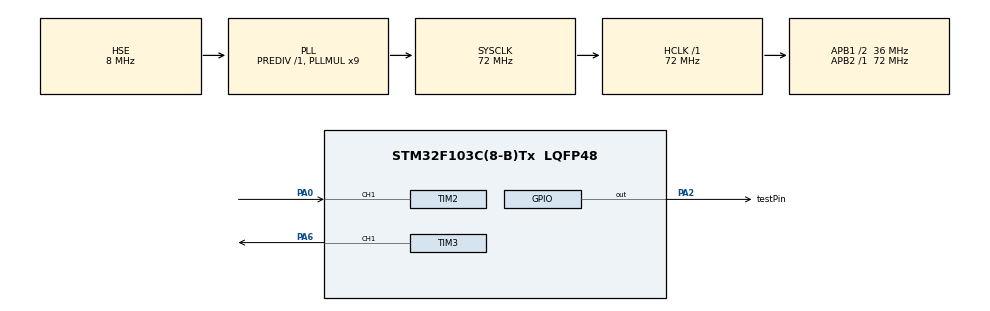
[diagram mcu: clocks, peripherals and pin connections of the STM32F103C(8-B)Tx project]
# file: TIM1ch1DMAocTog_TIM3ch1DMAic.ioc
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Dma.Request0=TIM2_CH1
Dma.Request1=TIM2_CH2/CH4
Dma.Request2=TIM3_CH1/TRIG
Dma.TIM2_CH1.0.Direction=DMA_PERIPH_TO_MEMORY
Dma.TIM2_CH1.0.Instance=DMA1_Channel5
Dma.TIM2_CH1.0.MemDataAlignment=DMA_MDATAALIGN_WORD
Dma.TIM2_CH1.0.MemInc=DMA_MINC_ENABLE
Dma.TIM2_CH1.0.Mode=DMA_CIRCULAR
Dma.TIM2_CH1.0.PeriphDataAlignment=DMA_PDATAALIGN_HALFWORD
Dma.TIM2_CH1.0.PeriphInc=DMA_PINC_DISABLE
Dma.TIM2_CH1.0.Priority=DMA_PRIORITY_HIGH
Dma.TIM2_CH2/CH4.1.Direction=DMA_PERIPH_TO_MEMORY
Dma.TIM2_CH2/CH4.1.Instance=DMA1_Channel7
Dma.TIM2_CH2/CH4.1.MemDataAlignment=DMA_MDATAALIGN_WORD
Dma.TIM2_CH2/CH4.1.MemInc=DMA_MINC_ENABLE
Dma.TIM2_CH2/CH4.1.Mode=DMA_CIRCULAR
Dma.TIM2_CH2/CH4.1.PeriphDataAlignment=DMA_PDATAALIGN_HALFWORD
Dma.TIM2_CH2/CH4.1.PeriphInc=DMA_PINC_DISABLE
Dma.TIM2_CH2/CH4.1.Priority=DMA_PRIORITY_HIGH
Dma.TIM3_CH1/TRIG.2.Direction=DMA_MEMORY_TO_PERIPH
Dma.TIM3_CH1/TRIG.2.Instance=DMA1_Channel6
Dma.TIM3_CH1/TRIG.2.MemDataAlignment=DMA_MDATAALIGN_WORD
Dma.TIM3_CH1/TRIG.2.MemInc=DMA_MINC_ENABLE
Dma.TIM3_CH1/TRIG.2.Mode=DMA_CIRCULAR
Dma.TIM3_CH1/TRIG.2.PeriphDataAlignment=DMA_PDATAALIGN_HALFWORD
Dma.TIM3_CH1/TRIG.2.PeriphInc=DMA_PINC_DISABLE
Dma.TIM3_CH1/TRIG.2.Priority=DMA_PRIORITY_HIGH
Mcu.Family=STM32F1
Mcu.Name=STM32F103C(8-B)Tx
Mcu.Package=LQFP48
NVIC.DMA1_Channel5_IRQn=true\:0\:0\:false\:false\:true
NVIC.DMA1_Channel6_IRQn=true\:0\:0\:false\:false\:true
NVIC.DMA1_Channel7_IRQn=true\:0\:0\:false\:false\:true
NVIC.PriorityGroup=NVIC_PRIORITYGROUP_4
PA0-WKUP.Signal=S_TIM2_CH1_ETR
PA13.Mode=Serial_Wire
PA13.Signal=SYS_JTMS-SWDIO
PA14.Mode=Serial_Wire
PA14.Signal=SYS_JTCK-SWCLK
PA2.GPIO_Label=testPin
PA2.GPIO_Speed=GPIO_SPEED_FREQ_HIGH
PA2.PinState=GPIO_PIN_SET
PA2.Signal=GPIO_Output
PA6.GPIO_Speed=GPIO_SPEED_FREQ_HIGH
PA6.Signal=S_TIM3_CH1
PD0-OSC_IN.Mode=HSE-External-Oscillator
PD0-OSC_IN.Signal=RCC_OSC_IN
PD1-OSC_OUT.Mode=HSE-External-Oscillator
PD1-OSC_OUT.Signal=RCC_OSC_OUT
ProjectManager.HeapSize=0x200
ProjectManager.StackSize=0x400
ProjectManager.TargetToolchain=SW4STM32
RCC.AHBFreq_Value=72000000
RCC.APB1CLKDivider=RCC_HCLK_DIV2
RCC.APB1Freq_Value=36000000
RCC.APB1TimFreq_Value=72000000
RCC.APB2Freq_Value=72000000
RCC.APB2TimFreq_Value=72000000
RCC.HCLKFreq_Value=72000000
RCC.PLLMUL=RCC_PLL_MUL9
RCC.PLLSourceVirtual=RCC_PLLSOURCE_HSE
RCC.SYSCLKFreq_VALUE=72000000
RCC.SYSCLKSource=RCC_SYSCLKSOURCE_PLLCLK
RCC.USBFreq_Value=72000000
SH.S_TIM2_CH1_ETR.0=TIM2_CH1,Input_Capture1_from_TI1
SH.S_TIM2_CH1_ETR.1=TIM2_CH1,Input_Capture2_from_TI1
SH.S_TIM2_CH1_ETR.2=TIM2_CH1,TriggerSource_TI1FP1
SH.S_TIM3_CH1.0=TIM3_CH1,Output Compare1 CH1
TIM2.Channel-Input_Capture1_from_TI1=TIM_CHANNEL_1
TIM2.Channel-Input_Capture2_from_TI1=TIM_CHANNEL_2
TIM2.ICPolarity_CH1=TIM_INPUTCHANNELPOLARITY_FALLING
TIM2.TIM_MasterOutputTrigger=TIM_TRGO_RESET
TIM3.Channel-Output\ Compare1\ CH1=TIM_CHANNEL_1
TIM3.OCMode_1=TIM_OCMODE_TOGGLE
TIM3.TIM_MasterOutputTrigger=TIM_TRGO_OC1
VP_TIM2_VS_ControllerModeReset.Mode=Reset Mode
board=TIM1ch1DMAocTog_TIM3ch1DMAic

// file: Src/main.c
/**
  ******************************************************************************
  * File Name          : main.c
  * Description        : Main program body
  ******************************************************************************
  ** This notice applies to any and all portions of this file
  * that are not between comment pairs USER CODE BEGIN and
  * USER CODE END. Other portions of this file, whether
  * inserted by the user or by software development tools
  * are owned by their respective copyright owners.
  *
  * COPYRIGHT(c) 2017 STMicroelectronics
  *
  * Redistribution and use in source and binary forms, with or without modification,
  * are permitted provided that the following conditions are met:
  *   1. Redistributions of source code must retain the above copyright notice,
  *      this list of conditions and the following disclaimer.
  *   2. Redistributions in binary form must reproduce the above copyright notice,
  *      this list of conditions and the following disclaimer in the documentation
  *      and/or other materials provided with the distribution.
  *   3. Neither the name of STMicroelectronics nor the names of its contributors
  *      may be used to endorse or promote products derived from this software
  *      without specific prior written permission.
  *
  * THIS SOFTWARE IS PROVIDED BY THE COPYRIGHT HOLDERS AND CONTRIBUTORS "AS IS"
  * AND ANY EXPRESS OR IMPLIED WARRANTIES, INCLUDING, BUT NOT LIMITED TO, THE
  * IMPLIED WARRANTIES OF MERCHANTABILITY AND FITNESS FOR A PARTICULAR PURPOSE ARE
  * DISCLAIMED. IN NO EVENT SHALL THE COPYRIGHT HOLDER OR CONTRIBUTORS BE LIABLE
  * FOR ANY DIRECT, INDIRECT, INCIDENTAL, SPECIAL, EXEMPLARY, OR CONSEQUENTIAL
  * DAMAGES (INCLUDING, BUT NOT LIMITED TO, PROCUREMENT OF SUBSTITUTE GOODS OR
  * SERVICES; LOSS OF USE, DATA, OR PROFITS; OR BUSINESS INTERRUPTION) HOWEVER
  * CAUSED AND ON ANY THEORY OF LIABILITY, WHETHER IN CONTRACT, STRICT LIABILITY,
  * OR TORT (INCLUDING NEGLIGENCE OR OTHERWISE) ARISING IN ANY WAY OUT OF THE USE
  * OF THIS SOFTWARE, EVEN IF ADVISED OF THE POSSIBILITY OF SUCH DAMAGE.
  *
  ******************************************************************************
  */
#include "main.h"
#include "stm32f1xx_hal.h"

TIM_HandleTypeDef htim2;
TIM_HandleTypeDef htim3;
DMA_HandleTypeDef hdma_tim2_ch1;
DMA_HandleTypeDef hdma_tim2_ch2_ch4;
DMA_HandleTypeDef hdma_tim3_ch1_trig;

/* USER CODE BEGIN PV */
/* Private variables ---------------------------------------------------------*/
/* Timer handler declaration */
TIM_HandleTypeDef TimHandle3;
TIM_HandleTypeDef TimHandle2;

/* Timer Output Compare Configuration Structure declaration */
TIM_OC_InitTypeDef sConfig;
TIM_IC_InitTypeDef sICConfig;

/* Capture Compare buffer */
uint32_t aCCValue_Buffer[2] = { 0, 0};//, 0 };
uint32_t icBuffer1[4] = {0, 0, 0, 0};
uint32_t icBuffer2[4] = {0, 0, 0, 0};

/* Timer Period*/
uint32_t uhTimerPeriod = 0;

uint32_t counter = 0;
uint32_t uhCapture = 0;

/* USER CODE END PV */

void SystemClock_Config(void);
static void MX_GPIO_Init(void);
static void MX_DMA_Init(void);
static void MX_TIM2_Init(void);
static void MX_TIM3_Init(void);

void HAL_TIM_MspPostInit(TIM_HandleTypeDef *htim);

/* USER CODE BEGIN PFP */
/* Private function prototypes -----------------------------------------------*/

/* USER CODE END PFP */

/* USER CODE BEGIN 0 */
int c = 0;
/* USER CODE END 0 */

int main(void)
{

  /* MCU Configuration----------------------------------------------------------*/

  /* Reset of all peripherals, Initializes the Flash interface and the Systick. */
  HAL_Init();

  /* Configure the system clock */
  SystemClock_Config();

  /* Initialize all configured peripherals */
  MX_GPIO_Init();
  MX_DMA_Init();
  MX_TIM2_Init();
  MX_TIM3_Init();

  /* USER CODE BEGIN 2 */
  	uhTimerPeriod = (uint32_t) ((SystemCoreClock / 360000) - 1);
  	//minumum pulse to put is 12??
  	aCCValue_Buffer[0] =  //12;//2;//8999;
  			(uint32_t) (((uint32_t) 10 * (uhTimerPeriod - 1)) / 100);
  	aCCValue_Buffer[1] = //(uint32_t) ((SystemCoreClock / 4000000) - 1 + aCCValue_Buffer[0]);
  			(uint32_t) (((uint32_t) 30 * (uhTimerPeriod - 1)) / 100);
//  	aCCValue_Buffer[2] = //(uint32_t) ((SystemCoreClock / 400000) - 1 + aCCValue_Buffer[1]);
//  			(uint32_t) (((uint32_t) 75 * (uhTimerPeriod - 1)) / 100);
//  	aCCValue_Buffer[3] = //17998;
//  				(uint32_t) (((uint32_t) 95 * (uhTimerPeriod - 1)) / 100);

  	TimHandle3.Instance = TIM3;
//  	TIM3->CNT = 0;
  	TimHandle3.Init.Period = uhTimerPeriod;
  	TimHandle3.Init.RepetitionCounter = 0;
  	TimHandle3.Init.Prescaler = 0;
  	TimHandle3.Init.ClockDivision = 0;
  	TimHandle3.Init.CounterMode = TIM_COUNTERMODE_UP;
  	if (HAL_TIM_OC_Init(&TimHandle3) != HAL_OK) {
  		/* Initialization Error */
  		Error_Handler();
  	}

	__HAL_TIM_CLEAR_FLAG(&TimHandle3, TIM_FLAG_UPDATE);
  	sConfig.OCMode = TIM_OCMODE_FORCED_ACTIVE;
  	sConfig.OCPolarity = TIM_OCPOLARITY_HIGH;//TIM_OCPOLARITY_HIGH;
//  	sConfig.Pulse = uhTimerPeriod;

	if (HAL_TIM_OC_ConfigChannel(&TimHandle3, &sConfig, TIM_CHANNEL_1) != HAL_OK)
  	{
  		Error_Handler();
  	}
  	if (HAL_TIM_OC_Start(&TimHandle3, TIM_CHANNEL_1))//, TIM_CHANNEL_1, aCCValue_Buffer, 4) != HAL_OK)
  	{
  		Error_Handler();
  	}

//  	while(__HAL_TIM_GET_FLAG(&TimHandle3, TIM_FLAG_CC1) != SET);
  	HAL_GPIO_WritePin(testPin_Port, testPin, GPIO_PIN_SET);

  	sConfig.OCMode = TIM_OCMODE_FORCED_INACTIVE;
//  	sConfig.OCPolarity = TIM_OCPOLARITY_HIGH;//TIM_OCPOLARITY_HIGH;
//  	sConfig.Pulse = uhTimerPeriod;

	if (HAL_TIM_OC_ConfigChannel(&TimHandle3, &sConfig, TIM_CHANNEL_1) != HAL_OK)
  	{
  		Error_Handler();
  	}
  	if (HAL_TIM_OC_Start(&TimHandle3, TIM_CHANNEL_1))//, TIM_CHANNEL_1, aCCValue_Buffer, 4) != HAL_OK)
  	{
  		Error_Handler();
  	}

//  	while(__HAL_TIM_GET_FLAG(&TimHandle3, TIM_FLAG_CC1) != SET);
  	HAL_GPIO_WritePin(testPin_Port, testPin, GPIO_PIN_RESET);

//  	sConfig.OCMode = TIM_OCMODE_TOGGLE;
//  	sConfig.OCPolarity = TIM_OCPOLARITY_HIGH;
//  	sConfig.Pulse = aCCValue_Buffer[0];//0;//aCCValue_Buffer[0];
//  	if (HAL_TIM_OC_ConfigChannel(&TimHandle3, &sConfig, TIM_CHANNEL_1) != HAL_OK)
//  	{
//  		/* Configuration Error */
//  		Error_Handler();
//  	}
//
//  	/*##-3- Start PWM signal generation in DMA mode ############################*/
//  	if (HAL_TIM_OC_Start_DMA(&TimHandle3, TIM_CHANNEL_1, aCCValue_Buffer, 3) != HAL_OK)
//  	{
//  		/* Starting PWM generation Error */
//  		Error_Handler();
//  	}

//  	TimHandle2.Instance = TIM2;
//  	TimHandle2.Init.Period            = 0xFFFFFFFF;
//	TimHandle2.Init.Prescaler         = 0;
//	TimHandle2.Init.ClockDivision     = 0;
//	TimHandle2.Init.CounterMode       = TIM_COUNTERMODE_UP;
//	TimHandle2.Init.RepetitionCounter = 0;
//
//    if(HAL_TIM_IC_Init(&TimHandle2) != HAL_OK)
//    {
//      /* Initialization Error */
//      Error_Handler();
//    }
//
//    /* Configure the Input Capture of channel 2 */
//    sICConfig.ICPolarity  = TIM_ICPOLARITY_FALLING;
//    sICConfig.ICSelection = TIM_ICSELECTION_DIRECTTI;
//    sICConfig.ICPrescaler = TIM_ICPSC_DIV1;
//    sICConfig.ICFilter    = 0;
//    if(HAL_TIM_IC_ConfigChannel(&TimHandle2, &sICConfig, TIM_CHANNEL_2) != HAL_OK)
//    {
//      /* Configuration Error */
//      Error_Handler();
//    }
//
////    #ifdef FALLING_EDGE_CAPTURE
//      sICConfig.ICPolarity  = TIM_ICPOLARITY_RISING;
//      sICConfig.ICSelection = TIM_ICSELECTION_INDIRECTTI;
//      sICConfig.ICPrescaler = TIM_ICPSC_DIV1;
//      sICConfig.ICFilter    = 0;
//      if(HAL_TIM_IC_ConfigChannel(&TimHandle2, &sICConfig, TIM_CHANNEL_1) != HAL_OK)
//      {
//        /* Configuration Error */
//        Error_Handler();
//      }
//
//
//      sICConfig.ICPolarity  = TIM_ICPOLARITY_FALLING;
//
//     if (HAL_TIM_IC_Start_DMA(&TimHandle2, TIM_CHANNEL_2, icBuffer1, 5) != HAL_OK)
//     {
//       /* Initialization Error */
//       Error_Handler();
//     }
//
//
//     sICConfig.ICPolarity  = TIM_ICPOLARITY_RISING;
//     if (HAL_TIM_IC_Start_DMA(&TimHandle2, TIM_CHANNEL_1, icBuffer1, 5) != HAL_OK)
//    {
//         // Initialization Error - FAILS HERE DUE TO TIM2 HANDLE BEING BUSY
//       Error_Handler();
//     }

  /* USER CODE END 2 */

  /* Infinite loop */
  while (1)
  {

  /* USER CODE BEGIN 3 */
	  if(icBuffer1 > 0)
		  c--;
	  else
		  c++;
  }
  /* USER CODE END 3 */

}

/** System Clock Configuration
*/
void SystemClock_Config(void)
{

  RCC_OscInitTypeDef RCC_OscInitStruct;
  RCC_ClkInitTypeDef RCC_ClkInitStruct;

    /**Initializes the CPU, AHB and APB busses clocks
    */
  RCC_OscInitStruct.OscillatorType = RCC_OSCILLATORTYPE_HSE;
  RCC_OscInitStruct.HSEState = RCC_HSE_ON;
  RCC_OscInitStruct.HSEPredivValue = RCC_HSE_PREDIV_DIV1;
  RCC_OscInitStruct.HSIState = RCC_HSI_ON;
  RCC_OscInitStruct.PLL.PLLState = RCC_PLL_ON;
  RCC_OscInitStruct.PLL.PLLSource = RCC_PLLSOURCE_HSE;
  RCC_OscInitStruct.PLL.PLLMUL = RCC_PLL_MUL9;
  if (HAL_RCC_OscConfig(&RCC_OscInitStruct) != HAL_OK)
  {
    _Error_Handler(__FILE__, __LINE__);
  }

    /**Initializes the CPU, AHB and APB busses clocks
    */
  RCC_ClkInitStruct.ClockType = RCC_CLOCKTYPE_HCLK|RCC_CLOCKTYPE_SYSCLK
                              |RCC_CLOCKTYPE_PCLK1|RCC_CLOCKTYPE_PCLK2;
  RCC_ClkInitStruct.SYSCLKSource = RCC_SYSCLKSOURCE_PLLCLK;
  RCC_ClkInitStruct.AHBCLKDivider = RCC_SYSCLK_DIV1;
  RCC_ClkInitStruct.APB1CLKDivider = RCC_HCLK_DIV2;
  RCC_ClkInitStruct.APB2CLKDivider = RCC_HCLK_DIV1;

  if (HAL_RCC_ClockConfig(&RCC_ClkInitStruct, FLASH_LATENCY_2) != HAL_OK)
  {
    _Error_Handler(__FILE__, __LINE__);
  }

    /**Configure the Systick interrupt time
    */
  HAL_SYSTICK_Config(HAL_RCC_GetHCLKFreq()/1000);

    /**Configure the Systick
    */
  HAL_SYSTICK_CLKSourceConfig(SYSTICK_CLKSOURCE_HCLK);

  /* SysTick_IRQn interrupt configuration */
  HAL_NVIC_SetPriority(SysTick_IRQn, 0, 0);
}

/* TIM2 init function */
static void MX_TIM2_Init(void)
{

  TIM_SlaveConfigTypeDef sSlaveConfig;
  TIM_MasterConfigTypeDef sMasterConfig;
  TIM_IC_InitTypeDef sConfigIC;

  htim2.Instance = TIM2;
  htim2.Init.Prescaler = 0;
  htim2.Init.CounterMode = TIM_COUNTERMODE_UP;
  htim2.Init.Period = 0;
  htim2.Init.ClockDivision = TIM_CLOCKDIVISION_DIV1;
  if (HAL_TIM_Base_Init(&htim2) != HAL_OK)
  {
    _Error_Handler(__FILE__, __LINE__);
  }

  if (HAL_TIM_IC_Init(&htim2) != HAL_OK)
  {
    _Error_Handler(__FILE__, __LINE__);
  }

  sSlaveConfig.SlaveMode = TIM_SLAVEMODE_RESET;
  sSlaveConfig.InputTrigger = TIM_TS_TI1FP1;
  sSlaveConfig.TriggerPolarity = TIM_INPUTCHANNELPOLARITY_FALLING;
  sSlaveConfig.TriggerFilter = 0;
  if (HAL_TIM_SlaveConfigSynchronization(&htim2, &sSlaveConfig) != HAL_OK)
  {
    _Error_Handler(__FILE__, __LINE__);
  }

  sMasterConfig.MasterOutputTrigger = TIM_TRGO_RESET;
  sMasterConfig.MasterSlaveMode = TIM_MASTERSLAVEMODE_DISABLE;
  if (HAL_TIMEx_MasterConfigSynchronization(&htim2, &sMasterConfig) != HAL_OK)
  {
    _Error_Handler(__FILE__, __LINE__);
  }

  sConfigIC.ICPolarity = TIM_INPUTCHANNELPOLARITY_FALLING;
  sConfigIC.ICSelection = TIM_ICSELECTION_DIRECTTI;
  sConfigIC.ICPrescaler = TIM_ICPSC_DIV1;
  sConfigIC.ICFilter = 0;
  if (HAL_TIM_IC_ConfigChannel(&htim2, &sConfigIC, TIM_CHANNEL_1) != HAL_OK)
  {
    _Error_Handler(__FILE__, __LINE__);
  }

  sConfigIC.ICPolarity = TIM_INPUTCHANNELPOLARITY_RISING;
  sConfigIC.ICSelection = TIM_ICSELECTION_INDIRECTTI;
  if (HAL_TIM_IC_ConfigChannel(&htim2, &sConfigIC, TIM_CHANNEL_2) != HAL_OK)
  {
    _Error_Handler(__FILE__, __LINE__);
  }

}

/* TIM3 init function */
static void MX_TIM3_Init(void)
{

  TIM_MasterConfigTypeDef sMasterConfig;
  TIM_OC_InitTypeDef sConfigOC;

  htim3.Instance = TIM3;
  htim3.Init.Prescaler = 0;
  htim3.Init.CounterMode = TIM_COUNTERMODE_UP;
  htim3.Init.Period = 0;
  htim3.Init.ClockDivision = TIM_CLOCKDIVISION_DIV1;
  if (HAL_TIM_OC_Init(&htim3) != HAL_OK)
  {
    _Error_Handler(__FILE__, __LINE__);
  }

  sMasterConfig.MasterOutputTrigger = TIM_TRGO_OC1;
  sMasterConfig.MasterSlaveMode = TIM_MASTERSLAVEMODE_DISABLE;
  if (HAL_TIMEx_MasterConfigSynchronization(&htim3, &sMasterConfig) != HAL_OK)
  {
    _Error_Handler(__FILE__, __LINE__);
  }

  sConfigOC.OCMode = TIM_OCMODE_TOGGLE;
  sConfigOC.Pulse = 0;
  sConfigOC.OCPolarity = TIM_OCPOLARITY_HIGH;
  sConfigOC.OCFastMode = TIM_OCFAST_DISABLE;
  if (HAL_TIM_OC_ConfigChannel(&htim3, &sConfigOC, TIM_CHANNEL_1) != HAL_OK)
  {
    _Error_Handler(__FILE__, __LINE__);
  }

  HAL_TIM_MspPostInit(&htim3);

}

static void MX_DMA_Init(void)
{
  /* DMA controller clock enable */
  __HAL_RCC_DMA1_CLK_ENABLE();

  /* DMA interrupt init */
  /* DMA1_Channel5_IRQn interrupt configuration */
  HAL_NVIC_SetPriority(DMA1_Channel5_IRQn, 0, 0);
  HAL_NVIC_EnableIRQ(DMA1_Channel5_IRQn);
  /* DMA1_Channel6_IRQn interrupt configuration */
  HAL_NVIC_SetPriority(DMA1_Channel6_IRQn, 0, 0);
  HAL_NVIC_EnableIRQ(DMA1_Channel6_IRQn);
  /* DMA1_Channel7_IRQn interrupt configuration */
  HAL_NVIC_SetPriority(DMA1_Channel7_IRQn, 0, 0);
  HAL_NVIC_EnableIRQ(DMA1_Channel7_IRQn);

}

/** Configure pins as
        * Analog
        * Input
        * Output
        * EVENT_OUT
        * EXTI
*/
static void MX_GPIO_Init(void)
{

  GPIO_InitTypeDef GPIO_InitStruct;

  /* GPIO Ports Clock Enable */
  __HAL_RCC_GPIOD_CLK_ENABLE();
  __HAL_RCC_GPIOA_CLK_ENABLE();

  /*Configure GPIO pin Output Level */
  HAL_GPIO_WritePin(testPin_Port, testPin, GPIO_PIN_RESET);

  /*Configure GPIO pin : testPin_Pin */
  GPIO_InitStruct.Pin = testPin;
  GPIO_InitStruct.Mode = GPIO_MODE_OUTPUT_PP;
  GPIO_InitStruct.Speed = GPIO_SPEED_FREQ_HIGH;
  HAL_GPIO_Init(testPin_Port, &GPIO_InitStruct);

}

void _Error_Handler(char * file, int line)
{
  /* USER CODE BEGIN Error_Handler_Debug */
  /* User can add his own implementation to report the HAL error return state */
  while(1)
  {
	  c--;
  }
  /* USER CODE END Error_Handler_Debug */
}

/************************ (C) COPYRIGHT STMicroelectronics *****END OF FILE****/
